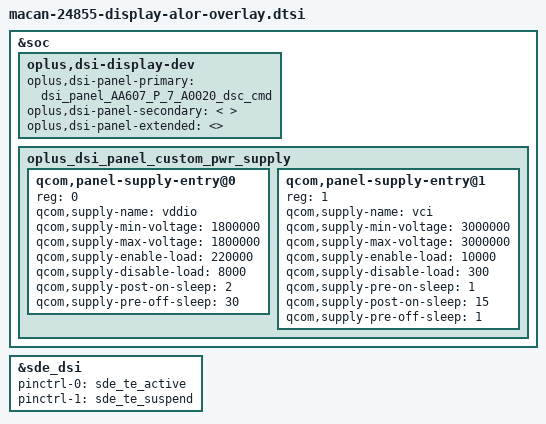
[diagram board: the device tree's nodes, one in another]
#include "panel/dsi-panel-AA607-P-7-A0020-dsc-cmd.dtsi"

&soc {
	oplus,dsi-display-dev {
		oplus,dsi-panel-primary = <
			&dsi_panel_AA607_P_7_A0020_dsc_cmd
		>;
		oplus,dsi-panel-secondary = <
		>;
		oplus,dsi-panel-extended = <>;
	};

	oplus_dsi_panel_custom_pwr_supply: oplus_dsi_panel_custom_pwr_supply {
		#address-cells = <1>;
		#size-cells = <0>;

		qcom,panel-supply-entry@0 {
			reg = <0>;
			qcom,supply-name = "vddio";
			qcom,supply-min-voltage = <1800000>;
			qcom,supply-max-voltage = <1800000>;
			qcom,supply-enable-load = <220000>;
			qcom,supply-disable-load = <8000>;
			qcom,supply-post-on-sleep = <2>;
			qcom,supply-pre-off-sleep = <30>;
		};

		qcom,panel-supply-entry@1 {
			reg = <1>;
			qcom,supply-name = "vci";
			qcom,supply-min-voltage = <3000000>;
			qcom,supply-max-voltage = <3000000>;
			qcom,supply-enable-load = <10000>;
			qcom,supply-disable-load = <300>;
			qcom,supply-pre-on-sleep = <1>;
			qcom,supply-post-on-sleep = <15>;
			qcom,supply-pre-off-sleep = <1>;
		};
	};
};

&sde_dsi {
	pinctrl-0 = <&sde_te_active>;
	pinctrl-1 = <&sde_te_suspend>;
};
